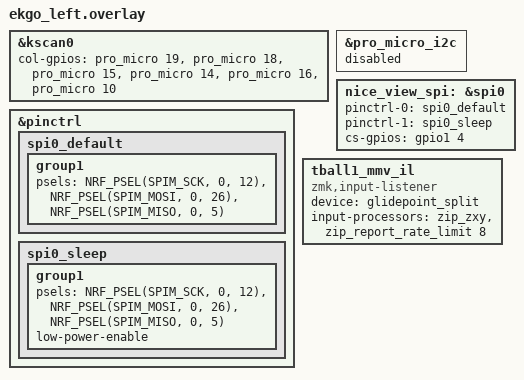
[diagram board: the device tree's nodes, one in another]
/*
 * Copyright (c) 2020 The ZMK Contributors
 *
 * SPDX-License-Identifier: MIT
 */

#include "ekgo.dtsi"

&kscan0 {
    col-gpios
        = <&pro_micro 19 GPIO_ACTIVE_HIGH>
		, <&pro_micro 18 GPIO_ACTIVE_HIGH>
		, <&pro_micro 15 GPIO_ACTIVE_HIGH>
		, <&pro_micro 14 GPIO_ACTIVE_HIGH>
		, <&pro_micro 16 GPIO_ACTIVE_HIGH>
        , <&pro_micro 10 GPIO_ACTIVE_HIGH>
        ;
};

&pinctrl {
    spi0_default: spi0_default {
        group1 {
            psels = <NRF_PSEL(SPIM_SCK,  0, 12)>,
                    <NRF_PSEL(SPIM_MOSI, 0, 26)>,
                    <NRF_PSEL(SPIM_MISO, 0, 5)>; 
        };
    };
    spi0_sleep: spi0_sleep {
        group1 {
            psels = <NRF_PSEL(SPIM_SCK,  0, 12)>,  
                    <NRF_PSEL(SPIM_MOSI, 0, 26)>,
                    <NRF_PSEL(SPIM_MISO, 0, 5)>; 
            low-power-enable;
        };
    };
};


&pro_micro_i2c {
    status = "disabled";
};

nice_view_spi: &spi0 {
    status = "okay";
    pinctrl-0 = <&spi0_default>;
    pinctrl-1 = <&spi0_sleep>;
    pinctrl-names = "default", "sleep";
    cs-gpios = <&gpio1 4 GPIO_ACTIVE_HIGH>;
};

// &glidepoint_listener {
//     status = "okay";
// };

/* Add the decompressor (zip_zxy) on central overlay */
#include <input/processors/xyz.dtsi>
tball1_mmv_il {
  compatible = "zmk,input-listener";
  device = <&glidepoint_split>;

  /* preppend Z-to-XY processor on receiving side */
  input-processors = <&zip_zxy>, <&zip_report_rate_limit 8>;
  /* NOTE: &zip_report_rate_limit is avaliable at https://github.com/badjeff/zmk-input-processor-report-rate-limit */
};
